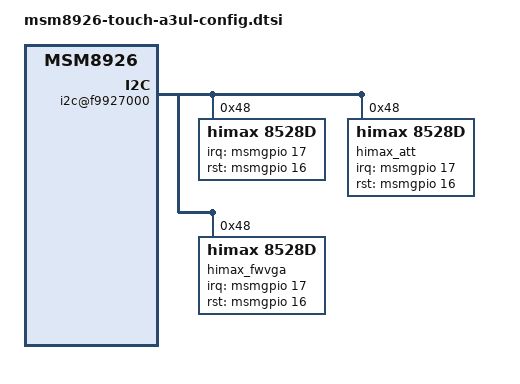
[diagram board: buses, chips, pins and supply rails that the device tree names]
/* Copyright (c) 2013, The Linux Foundation. All rights reserved.
 *
 * This program is free software; you can redistribute it and/or modify
 * it under the terms of the GNU General Public License version 2 and
 * only version 2 as published by the Free Software Foundation.
 *
 * This program is distributed in the hope that it will be useful,
 * but WITHOUT ANY WARRANTY; without even the implied warranty of
 * MERCHANTABILITY or FITNESS FOR A PARTICULAR PURPOSE.  See the
 * GNU General Public License for more details.
 */

&soc {
	i2c@f9927000 { /* BLSP1 QUP5 */
	himax@48 {
			compatible               	= "himax,8528d";
			reg                      		= <0x48>;
			interrupt-parent         	= <&msmgpio>;
			interrupts               	= <17 0x2>;
			himax,panel-coords   	= <0 810 0 1440>;
			himax,display-coords 	= <0 540 0 960>;
			himax,irq-gpio       	= <&msmgpio 17 0x00>;
			himax,rst-gpio       	= <&msmgpio 16 0x00>;
			report_type              	= <1>;

			config0 {	//YFO edge lamination
				sensor_id   	= <0x11>;
				himax,tw-coords   	= <0 810 0 1440>;
				himax,pl-coords 	= <0 540 0 960>;
				fw_ver     	= <0xC1>;
				c1 =[37 FF 08 FF 08];
				c2 =[3F 00];
				c3 =[62 01 00 21 00 00 00 00 00 11 11];
				c4 =[63 01 00 31 02 00 00 00 00 11 11];
				c5 =[64 01 00 21 03 00 00 00 00 11 11];
				c6 =[65 01 00 31 02 00 00 00 00 11 11];
				c7 =[66 01 00 21 03 00 00 00 00 11 11];
				c8 =[67 01 00 31 02 00 00 00 00 11 11];
				c9 =[68 01 00 21 03 00 00 00 00 11 11];
				c10 =[69 01 00 31 02 00 00 00 00 11 11];
				c11 =[6A 01 00 21 00 00 00 00 00 01 00];
				c12 =[6B 01 00 01 02 00 00 00 00 00 00];
				c13 =[6C 01 00 21 00 00 00 00 00 00 00];
				c14 =[6D 01 00 01 02 00 00 00 00 00 00];
				c15 =[6E 00 00 20 00 00 00 00 00 00 00];
				c16 =[6F 00 00 00 02 00 00 00 00 00 00];
				c17 =[70 00 00 00 00 00 00 00 00 00 00];
				c18 =[7B 03];
				c19 =[7C 00 D8 0C];
				c20 =[7F 00 04 0A 0A 04 00 00 00];
				c21 =[A4 94 62 94 86];
				c22 =[B4 05 01 02 02 02 04 07 05 07 05
				          07 05 07 08];
				c23 =[B9 01 36];
				c24 =[BA 00];
				c25 =[BB 00];
				c26 =[BC 00 00 00 00];
				c27 =[BD 04 0C];
				c28 =[C2 10 00 00 00 00 00 00 00];
				c29 =[C5 0C 1A 00 10 1A 1E 0B 1A 08 16];
				c30 =[C6 16 10 1E];
				c31 =[C9 00 00 00 10 12 14 16 18 1A 1C
				          20 22 24 26 11 13 15 17 19 1B
				          1D 21 23 25 00 00 00 00 00 00
				          00 00 00 00 00 00 00 00 00 00
				          00 00 00 00 00 00 00 00 00 00
				          00 00 00 00 00 00 00 00 00 00
				          00 00 00 00];
				c32 =[CB 01 F5 FF FF 01 00 05 00 7F 00
				          00 00];
				c33 =[D0 06 01];
				c34 =[D3 06 01];
				c35 =[D5 29 00 00 00 00 00 00 00 00 00
				          00 00 00 00 00 00];
				c36 =[40 0E 5A
				          5F 00 F0 10 00 00
				          38 0C 0B 12 0A 0C 0A 0C 0C 0C
				          24 20 40 40 3C 00 00 00 00 05
				          10 20];
				c37 =[40 94 08 80 83 84 00
				          48 24 0F 14 83 3C 00 00
				          11 00 41 42
				          0F 3F 00 12 00 00
				          10 02 3C 64 00 00];
				c38 =[40 18 47 47 04 14 00 00 00
				          04 06 24 05 05 00 00 00];
				c39 =[40 30 58 05 00 00 D8 0C 00 00 02
				          03 80 00 00 00 00
				          10 02 80 00 00 00 00 0C];
				c40 =[40 00 00 00 00 00 00 00 00
				          A0 82 2D 00
				          0C 15 A0 13
				          00 00 03 2A 05 A0];
				c41 =[40 04 A0 09 89 50 D5 08 00 7D 01
				          D4 49 CC 0C
				          06 AD 0D C5 56 2B 00 01 00 03
				          C0 4E 33 00];
				c42 =[40 00 00 00 00 00 00 00 00];
				c43_1 =[40 04 0C FF FF 08 0D 1A FF 03 0E
				             1B FF 09 0F 1C FF 02 10 1D FF
				             07 11 1E FF 05 12 1F FF 06 13
				             20];
				c43_2 =[40 FF 0A 14 FF FF 01 15 FF FF
				             0B 16 FF FF 00 17 FF FF FF 18
				             FF FF FF 19 FF FF FF FF FF FF];
				c44_1 =[40 A3 00 20 00 13 1E 32 00 00 00
				             00 00 00 00 00 00 00 00 00 00
				             00 00 00 00 00 00 00 00 00 00
				             56];
				c44_2 =[40 02 12 02 00 04];
				c45   =[40 00 00];
				};

			config1 {	//Henghao edge lamination
				sensor_id   	= <0x21>;
				himax,tw-coords   	= <0 810 0 1440>;
				himax,pl-coords 	= <0 540 0 960>;
				fw_ver     	= <0xC1>;
				c1 =[37 FF 08 FF 08];
				c2 =[3F 00];
				c3 =[62 01 00 21 00 00 00 00 00 33 33];
				c4 =[63 01 00 31 02 00 00 00 00 33 33];
				c5 =[64 01 00 21 03 00 00 00 00 33 33];
				c6 =[65 01 00 31 02 00 00 00 00 22 22];
				c7 =[66 01 00 21 03 00 00 00 00 22 22];
				c8 =[67 01 00 31 02 00 00 00 00 22 22];
				c9 =[68 01 00 21 03 00 00 00 00 22 22];
				c10 =[69 01 00 31 02 00 00 00 00 22 22];
				c11 =[6A 01 00 21 00 00 00 00 00 02 00];
				c12 =[6B 01 00 01 02 00 00 00 00 00 00];
				c13 =[6C 01 00 21 00 00 00 00 00 00 00];
				c14 =[6D 01 00 01 02 00 00 00 00 00 00];
				c15 =[6E 00 00 20 00 00 00 00 00 00 00];
				c16 =[6F 00 00 00 02 00 00 00 00 00 00];
				c17 =[70 00 00 00 00 00 00 00 00 00 00];
				c18 =[7B 03];
				c19 =[7C 00 D8 0C];
				c20 =[7F 00 04 0A 0A 04 00 00 00];
				c21 =[A4 94 62 94 86];
				c22 =[B4 06 01 02 02 02 03 0F 03 0F 03
				          0F 03 0F 08];
				c23 =[B9 01 36];
				c24 =[BA 00];
				c25 =[BB 00];
				c26 =[BC 00 00 00 00];
				c27 =[BD 04 0C];
				c28 =[C2 10 00 00 00 00 00 00 00];
				c29 =[C5 0A 1B 00 10 1A 1E 0B 1A 08 16];
				c30 =[C6 17 10 1E];
				c31 =[C9 00 00 00 26 24 22 20 1C 1A 18
				          16 14 12 10 25 23 21 1D 1B 19
				          17 15 13 11 00 00 00 00 00 00
				          00 00 00 00 00 00 00 00 00 00
				          00 00 00 00 00 00 00 00 00 00
				          00 00 00 00 00 00 00 00 00 00
				          00 00 00 00];
				c32 =[CB 01 F5 FF FF 01 00 05 00 5F 00
				          00 00];
				c33 =[D0 06 01];
				c34 =[D3 06 01];
				c35 =[D5 29 00 00 00 00 00 00 00 00 00
				          00 00 00 00 00 00];
				c36 =[40 0D 5A
				          5F 00 F0 10 00 00
				          38 0C 0B 12 0A 0C 0A 0C 0C 0C
				          24 20 40 40 3C 00 00 00 00 05
				          10 20];
				c37 =[40 94 08 80 83 84 00
				          48 24 0F 14 83 3C 00 00
				          11 00 41 42
				          0F 3F 00 12 00 00
				          10 02 3C 64 00 00];
				c38 =[40 18 3F 3F 04 14 00 00 00
				          04 06 24 06 06 00 00 00];
				c39 =[40 30 58 05 00 00 D8 0C 00 00 02
				          03 80 00 00 00 00
				          10 02 80 00 00 00 00 0C];
				c40 =[40 00 00 00 00 00 00 00 00
				          A0 82 2D 01
				          0C 15 A0 13
				          00 00 03 2A 05 A0];
				c41 =[40 04 A4 09 92 50 DD 08 00 7D 01
				          04 49 CC 0C
				          06 B1 0D CD 56 33 00 01 00 03
				          C0 4E 33 00];
				c42 =[40 00 00 00 00 00 00 00 00];
				c43_1 =[40 04 20 FF FF 08 1F 12 FF 03 1E
				             11 FF 09 1D 10 FF 02 1C 0F FF
				             07 1B 0E FF 05 1A 0D FF 06 19
				             0C];
				c43_2 =[40 FF 0A 18 FF FF 01 17 FF FF
				             0B 16 FF FF 00 15 FF FF FF 14
				             FF FF FF 13 FF FF FF FF FF FF];
				c44_1 =[40 A3 00 20 00 13 1E 32 00 00 00
				             00 00 00 00 00 00 00 00 00 00
				             00 00 00 00 00 00 00 00 00 00
				             56];
				c44_2 =[40 02 12 02 00 04];
				c45   =[40 00 00];
				};

			config2 {	//YFO edge lamination
				sensor_id   	= <0x22>;
				himax,tw-coords   	= <0 810 0 1440>;
				himax,pl-coords 	= <0 540 0 960>;
				fw_ver     	= <0xC1>;
				c1 =[37 FF 08 FF 08];
				c2 =[3F 00];
				c3 =[62 01 00 21 00 00 00 00 00 11 11];
				c4 =[63 01 00 31 02 00 00 00 00 11 11];
				c5 =[64 01 00 21 03 00 00 00 00 11 11];
				c6 =[65 01 00 31 02 00 00 00 00 11 11];
				c7 =[66 01 00 21 03 00 00 00 00 11 11];
				c8 =[67 01 00 31 02 00 00 00 00 11 11];
				c9 =[68 01 00 21 03 00 00 00 00 11 11];
				c10 =[69 01 00 31 02 00 00 00 00 11 11];
				c11 =[6A 01 00 21 00 00 00 00 00 01 00];
				c12 =[6B 01 00 01 02 00 00 00 00 00 00];
				c13 =[6C 01 00 21 00 00 00 00 00 00 00];
				c14 =[6D 01 00 01 02 00 00 00 00 00 00];
				c15 =[6E 00 00 20 00 00 00 00 00 00 00];
				c16 =[6F 00 00 00 02 00 00 00 00 00 00];
				c17 =[70 00 00 00 00 00 00 00 00 00 00];
				c18 =[7B 03];
				c19 =[7C 00 D8 0C];
				c20 =[7F 00 04 0A 0A 04 00 00 00];
				c21 =[A4 94 62 94 86];
				c22 =[B4 05 01 02 02 02 04 07 05 07 05
				          07 05 07 08];
				c23 =[B9 01 36];
				c24 =[BA 00];
				c25 =[BB 00];
				c26 =[BC 00 00 00 00];
				c27 =[BD 04 0C];
				c28 =[C2 10 00 00 00 00 00 00 00];
				c29 =[C5 0C 1A 00 10 1A 1E 0B 1A 08 16];
				c30 =[C6 16 10 1E];
				c31 =[C9 00 00 00 10 12 14 16 18 1A 1C
				          20 22 24 26 11 13 15 17 19 1B
				          1D 21 23 25 00 00 00 00 00 00
				          00 00 00 00 00 00 00 00 00 00
				          00 00 00 00 00 00 00 00 00 00
				          00 00 00 00 00 00 00 00 00 00
				          00 00 00 00];
				c32 =[CB 01 F5 FF FF 01 00 05 00 7F 00
				          00 00];
				c33 =[D0 06 01];
				c34 =[D3 06 01];
				c35 =[D5 29 00 00 00 00 00 00 00 00 00
				          00 00 00 00 00 00];
				c36 =[40 0E 5A
				          5F 00 F0 10 00 00
				          38 0C 0B 12 0A 0C 0A 0C 0C 0C
				          24 20 40 40 3C 00 00 00 00 05
				          10 20];
				c37 =[40 94 08 80 83 84 00
				          48 24 0F 14 83 3C 00 00
				          11 00 41 42
				          0F 3F 00 12 00 00
				          10 02 3C 64 00 00];
				c38 =[40 18 47 47 04 14 00 00 00
				          04 06 24 05 05 00 00 00];
				c39 =[40 30 58 05 00 00 D8 0C 00 00 02
				          03 80 00 00 00 00
				          10 02 80 00 00 00 00 0C];
				c40 =[40 00 00 00 00 00 00 00 00
				          A0 82 2D 00
				          0C 15 A0 13
				          00 00 03 2A 05 A0];
				c41 =[40 04 A0 09 89 50 D5 08 00 7D 01
				          D4 49 CC 0C
				          06 AD 0D C5 56 2B 00 01 00 03
				          C0 4E 33 00];
				c42 =[40 00 00 00 00 00 00 00 00];
				c43_1 =[40 04 0C FF FF 08 0D 1A FF 03 0E
				             1B FF 09 0F 1C FF 02 10 1D FF
				             07 11 1E FF 05 12 1F FF 06 13
				             20];
				c43_2 =[40 FF 0A 14 FF FF 01 15 FF FF
				             0B 16 FF FF 00 17 FF FF FF 18
				             FF FF FF 19 FF FF FF FF FF FF];
				c44_1 =[40 A3 00 20 00 13 1E 32 00 00 00
				             00 00 00 00 00 00 00 00 00 00
				             00 00 00 00 00 00 00 00 00 00
				             56];
				c44_2 =[40 02 12 02 00 04];
				c45   =[40 00 00];
				};

			config3 {	//ENR-semi 2
				sensor_id   	= <0x12>;
				himax,tw-coords   	= <0 810 0 1440>;
				himax,pl-coords 	= <0 540 0 960>;
				fw_ver     	= <0x04>;
				c1 = [ 37 FF 08 FF 08];
				c2 = [ 3F 00];
				c3 = [ 62 01 00 21 00 00 00 00 00 22 12];
				c4 = [ 63 01 00 31 02 00 00 00 00 12 12];
				c5 = [ 64 01 00 21 03 00 00 00 00 12 22];
				c6 = [ 65 01 00 31 02 00 00 00 00 22 22];
				c7 = [ 66 01 00 21 03 00 00 00 00 22 22];
				c8 = [ 67 01 00 31 02 00 00 00 00 22 22];
				c9 = [ 68 01 00 21 03 00 00 00 00 22 22];
				c10 =[ 69 01 00 31 02 00 00 00 00 22 22];
				c11 =[ 6A 01 00 21 00 00 00 00 00 02 00];
				c12 =[ 6B 01 00 01 02 00 00 00 00 00 00];
				c13 =[ 6C 01 00 21 00 00 00 00 00 00 00];
				c14 =[ 6D 01 00 01 02 00 00 00 00 00 00];
				c15 =[ 6E 00 00 20 00 00 00 00 00 00 00];
				c16 =[ 6F 00 00 00 02 00 00 00 00 00 00];
				c17 =[ 70 00 00 00 00 00 00 00 00 00 00];
				c18 =[ 7B 03];
				c19 =[ 7C 00 D8 8C];
				c20 =[ 7F 00 04 0A 0A 04 00 00 00];
				c21 =[ A4 94 62 94 86];
				c22 =[ B4 04 01 01 01 01 03 0F 04 07 04
				           07 04 07 00];
				c23 =[ B9 01 36];
				c24 =[ BA 00];
				c25 =[ BB 00];
				c26 =[ BC 00 00 00 00];
				c27 =[ BD 04 0C];
				c28 =[ C2 10 00 00 00 00 00 00 00];
				c29 =[ C5 0A 1C 00 10 19 1F 0B 1D 08 16];
				c30 =[ C6 16 10 1E];
				c31 =[ C9 00 00 00 26 24 22 20 1C 1A 18
				           16 14 12 10 25 23 21 1D 1B 19
				           17 15 13 11 00 00 00 00 00 00
				           00 00 00 00 00 00 00 00 00 00
				           00 00 00 00 00 00 00 00 00 00
				           00 00 00 00 00 00 00 00 00 00
				           00 00 00 00];
				c32 =[ CB 01 F5 FF FF 01 00 05 00 9F 00
				           00 00];
				c33 =[ D0 06 01];
				c34 =[ D3 06 01];
				c35 =[ D5 29 00 00 00 00 00 00 00 00 00
				           00 00 00 00 00 00];
				c36 =[ 40 01 5A
				           5F 00 00 10 00 00
				           28 0C 0A 10 06 06 0C 0F 0F 0F
				           20 20 30 5A 00 00 00 00 00 00
				           00 00];
				c37 =[ 40 64 08 80 82 85 00
				           35 25 0F 0F 83 3C 00 00
				           11 00 00 00
				           08 08 00 08 00 1A
				           10 02 10 64 00 00];
				c38 =[ 40 40 57 57 0A 14 00 00 00
				           04 03 12 06 06 00 00 00];
				c39 =[ 40 18 18 05 00 00 D8 8C 00 00 42
				           03 00 00 00 00 00
				           10 02 80 00 00 00 00 0C];
				c40 =[ 40 10 12 20 32 01 04 07 09
				           96 6E 32 00
				           0C 15 A0 13
				           00 00 03 2A 05 A0];
				c41 =[ 40 00 00 00 00 49 8C 00 00 00 00
				           00 47 F3 00
				           00 00 00 00 49 8C 00 00 00 00
				           00 47 F3 00];
				c42 =[ 40 00 00 00 00 00 00 00 00];
				c43_1 =[ 40 03 20 FF FF 04 1F 12 FF 05 1E
				              11 FF 06 1D 10 FF 07 1C 0F FF
				              02 1B 0E FF 01 1A 0D FF 00 19
				              0C];
				c43_2 =[ 40 FF 08 18 FF FF 09 17 FF FF
				              0A 16 FF FF 0B 15 FF FF FF 14
				              FF FF FF 13 FF FF FF FF FF FF];
				c44_1 =[ 40 A3 00 20 00 13 1E 32 00 00 00
				              00 00 00 00 00 00 00 00 00 00
				              00 00 00 00 00 00 00 00 00 00
				              00];
				c44_2 =[ 40 00 00 00 00 00];
				c45   =[ 40 19 00];
			};
		};

		himax_att@48 {
			compatible               	= "himax,8528d";
			reg                      		= <0x48>;
			interrupt-parent         	= <&msmgpio>;
			interrupts               	= <17 0x2>;
			himax,panel-coords   	= <0 810 0 1440>;
			himax,display-coords 	= <0 540 0 960>;
			himax,irq-gpio       	= <&msmgpio 17 0x00>;
			himax,rst-gpio       	= <&msmgpio 16 0x00>;
			report_type              	= <1>;

			config0 {	//CP3-semi 3
				sensor_id   	= <0x11>;
				himax,tw-coords   	= <0 810 0 1440>;
				himax,pl-coords 	= <0 540 0 960>;
				fw_ver     	= <0x04>;
				c1 =[37 FF 08 FF 08];
				c2 =[3F 00];
				c3 =[62 01 00 21 00 00 00 00 00 22 22];
				c4 =[63 01 00 31 02 00 00 00 00 22 22];
				c5 =[64 01 00 21 03 00 00 00 00 22 22];
				c6 =[65 01 00 31 02 00 00 00 00 22 22];
				c7 =[66 01 00 21 03 00 00 00 00 22 22];
				c8 =[67 01 00 31 02 00 00 00 00 22 22];
				c9 =[68 00 00 20 03 00 00 00 00 22 22];
				c10 =[69 00 00 00 02 00 00 00 00 22 22];
				c11 =[6A 01 00 21 00 00 00 00 00 22 22];
				c12 =[6B 01 00 01 02 00 00 00 00 00 00];
				c13 =[6C 01 00 21 00 00 00 00 00 00 00];
				c14 =[6D 01 00 01 02 00 00 00 00 00 00];
				c15 =[6E 00 00 20 00 00 00 00 00 00 00];
				c16 =[6F 00 00 00 02 00 00 00 00 00 00];
				c17 =[70 00 00 00 00 00 00 00 00 00 00];
				c18 =[7B 03];
				c19 =[7C 00 D8 0C];
				c20 =[7F 00 04 0A 0A 04 00 00 00];
				c21 =[A4 94 62 94 86];
				c22 =[B4 08 01 02 02 02 02 07 02 07 02
				              07 02 07 08];
				c23 =[B9 01 56];
				c24 =[BA 00];
				c25 =[BB 00];
				c26 =[BC 00 00 00 00];
				c27 =[BD 04 0C];
				c28 =[C2 10 00 00 00 00 00 00 00];
				c29 =[C5 0C 1F 00 10 1A 1E 0B 1A 08 16];
				c30 =[C6 15 10 1E];
				c31 =[C9 00 00 00 10 12 14 16 18 1A 1C
				          20 22 24 11 13 15 17 19 1B 1D
				          21 23 25 00 00 00 00 00 00 00
				          00 00 00 00 00 00 00 00 00 00
				          00 00 00 00 00 00 00 00 00 00
				          00 00 00 00 00 00 00 00 00 00
				          00 00 00 00];
				c32 =[CB 01 F5 FF FF 01 00 05 00 5F 00
				          00 00];
				c33 =[D0 06 01];
				c34 =[D3 06 01];
				c35 =[D5 29 00 00 00 00 00 00 00 00 00
				          00 00 00 00 00 00];
				c36 =[40 01 5A
				          5F 00 F0 10 00 00
				          38 0C 0B 10 0A 0A 0A 0F 0F 0F
				          28 1C 40 40 28 00 00 00 00 05
				          10 20];
				c37 =[40 75 08 80 83 84 00
				          50 28 0F 0F 83 3C 00 00
				          11 00 41 52
				          0F 18 00 12 00 00
				          10 02 3C 64 00 00];
				c38 =[40 28 27 27 02 14 00 00 00
				          04 06 24 08 08 00 00 00];
				c39 =[40 20 34 05 00 00 D8 0C 00 00 02
				          03 11 00 00 00 00
				          10 02 80 00 00 00 00 0C];
				c40 =[40 00 00 00 00 00 00 00 00
				          A0 82 1E 00
				          0A 14 A0 13
				          00 00 03 2A 05 A0];
				c41 =[40 00 00 00 00 59 E4 00 00 00 00
				          00 51 00 00
				          00 00 00 00 59 E4 00 00 00 00
				          00 51 00 00];
				c42 =[40 00 00 00 00 00 00 00 00];
				c43_1 =[40 04 0A FF FF 06 0B 18 FF 03 0C
				             19 FF 07 0D 1A FF 02 0E 1B FF
				             05 0F 1C FF FF 10 1D FF FF 11
				             FF];
				c43_2 =[40 FF 08 12 FF FF 01 13 FF FF
				             09 14 FF FF 00 15 FF FF FF 16
				             FF FF FF 17 FF FF FF FF FF FF];
				c44_1 =[40 A3 00 20 00 13 1E 32 00 00 00
				             00 00 00 00 00 00 00 00 00 00
				             00 00 00 00 00 00 00 00 00 00
				             56];
				c44_2 =[40 02 12 02 00 04];
				c45   =[40 00 00];
				};

			config1 {	//YFO full lamination
				sensor_id   	= <0x22>;
				himax,tw-coords   	= <0 810 0 1440>;
				himax,pl-coords 	= <0 540 0 960>;
				fw_ver     	= <0xC1>;
				c1 =[37 FF 08 FF 08];
				c2 =[3F 00];
				c3 =[62 01 00 21 00 00 00 00 00 11 11];
				c4 =[63 01 00 31 02 00 00 00 00 11 11];
				c5 =[64 01 00 21 03 00 00 00 00 11 11];
				c6 =[65 01 00 31 02 00 00 00 00 22 22];
				c7 =[66 01 00 21 03 00 00 00 00 22 22];
				c8 =[67 01 00 31 02 00 00 00 00 22 22];
				c9 =[68 01 00 21 03 00 00 00 00 22 22];
				c10 =[69 01 00 31 02 00 00 00 00 22 22];
				c11 =[6A 01 00 21 00 00 00 00 00 02 00];
				c12 =[6B 01 00 01 02 00 00 00 00 00 00];
				c13 =[6C 01 00 21 00 00 00 00 00 00 00];
				c14 =[6D 01 00 01 02 00 00 00 00 00 00];
				c15 =[6E 00 00 20 00 00 00 00 00 00 00];
				c16 =[6F 00 00 00 02 00 00 00 00 00 00];
				c17 =[70 00 00 00 00 00 00 00 00 00 00];
				c18 =[7B 03];
				c19 =[7C 00 D8 0C];
				c20 =[7F 00 04 0A 0A 04 00 00 00];
				c21 =[A4 94 62 94 86];
				c22 =[B4 05 01 02 02 02 04 07 05 07 05
				          07 05 07 08];
				c23 =[B9 01 36];
				c24 =[BA 00];
				c25 =[BB 00];
				c26 =[BC 00 00 00 00];
				c27 =[BD 04 0C];
				c28 =[C2 10 00 00 00 00 00 00 00];
				c29 =[C5 0C 1A 00 10 1A 1E 0B 1A 08 16];
				c30 =[C6 16 10 1E];
				c31 =[C9 00 00 00 10 12 14 16 18 1A 1C
				          20 22 24 26 11 13 15 17 19 1B
				          1D 21 23 25 00 00 00 00 00 00
				          00 00 00 00 00 00 00 00 00 00
				          00 00 00 00 00 00 00 00 00 00
				          00 00 00 00 00 00 00 00 00 00
				          00 00 00 00];
				c32 =[CB 01 F5 FF FF 01 00 05 00 7F 00
				          00 00];
				c33 =[D0 06 01];
				c34 =[D3 06 01];
				c35 =[D5 29 00 00 00 00 00 00 00 00 00
				          00 00 00 00 00 00];
				c36 =[40 04 5A
				          5F 00 F0 10 00 00
				          38 0C 0B 12 0A 0C 0A 0C 0C 0C
				          28 1C 40 40 1C 00 00 00 00 05
				          10 20];
				c37 =[40 94 08 80 83 84 00
				          50 28 0F 14 83 3C 00 00
				          11 00 41 42
				          0F 1F 00 12 00 00
				          10 02 3C 64 00 00];
				c38 =[40 18 47 47 04 14 00 00 00
				          04 06 24 05 05 00 00 00];
				c39 =[40 30 60 05 00 00 D8 0C 00 00 02
				          03 00 00 00 00 00
				          10 02 80 00 00 00 00 0C];
				c40 =[40 00 00 00 00 00 00 00 00
				          A0 82 1E 00
				          0C 15 A0 13
				          00 00 03 2A 05 A0];
				c41 =[40 04 A0 09 89 50 D5 08 00 7D 01
				          D4 49 CC 0C
				          06 AD 0D C5 56 2B 00 01 00 03
				          C0 4E 33 00];
				c42 =[40 00 00 00 00 00 00 00 00];
				c43_1 =[40 04 0C FF FF 08 0D 1A FF 03 0E
				             1B FF 09 0F 1C FF 02 10 1D FF
				             07 11 1E FF 05 12 1F FF 06 13
				             20];
				c43_2 =[40 FF 0A 14 FF FF 01 15 FF FF
				             0B 16 FF FF 00 17 FF FF FF 18
				             FF FF FF 19 FF FF FF FF FF FF];
				c44_1 =[40 A3 00 20 00 13 1E 32 00 00 00
				             00 00 00 00 00 00 00 00 00 00
				             00 00 00 00 00 00 00 00 00 00
				             56];
				c44_2 =[40 02 12 02 00 04];
				c45   =[40 00 00];
				};

			config2 {	//ENR-semi 2
				sensor_id   	= <0x12>;
				himax,tw-coords   	= <0 810 0 1440>;
				himax,pl-coords 	= <0 540 0 960>;
				fw_ver     	= <0x04>;
				c1 = [ 37 FF 08 FF 08];
				c2 = [ 3F 00];
				c3 = [ 62 01 00 21 00 00 00 00 00 22 12];
				c4 = [ 63 01 00 31 02 00 00 00 00 12 12];
				c5 = [ 64 01 00 21 03 00 00 00 00 12 22];
				c6 = [ 65 01 00 31 02 00 00 00 00 22 22];
				c7 = [ 66 01 00 21 03 00 00 00 00 22 22];
				c8 = [ 67 01 00 31 02 00 00 00 00 22 22];
				c9 = [ 68 01 00 21 03 00 00 00 00 22 22];
				c10 =[ 69 01 00 31 02 00 00 00 00 22 22];
				c11 =[ 6A 01 00 21 00 00 00 00 00 02 00];
				c12 =[ 6B 01 00 01 02 00 00 00 00 00 00];
				c13 =[ 6C 01 00 21 00 00 00 00 00 00 00];
				c14 =[ 6D 01 00 01 02 00 00 00 00 00 00];
				c15 =[ 6E 00 00 20 00 00 00 00 00 00 00];
				c16 =[ 6F 00 00 00 02 00 00 00 00 00 00];
				c17 =[ 70 00 00 00 00 00 00 00 00 00 00];
				c18 =[ 7B 03];
				c19 =[ 7C 00 D8 8C];
				c20 =[ 7F 00 04 0A 0A 04 00 00 00];
				c21 =[ A4 94 62 94 86];
				c22 =[ B4 04 01 01 01 01 03 0F 04 07 04
				           07 04 07 00];
				c23 =[ B9 01 36];
				c24 =[ BA 00];
				c25 =[ BB 00];
				c26 =[ BC 00 00 00 00];
				c27 =[ BD 04 0C];
				c28 =[ C2 10 00 00 00 00 00 00 00];
				c29 =[ C5 0A 1C 00 10 19 1F 0B 1D 08 16];
				c30 =[ C6 16 10 1E];
				c31 =[ C9 00 00 00 26 24 22 20 1C 1A 18
				           16 14 12 10 25 23 21 1D 1B 19
				           17 15 13 11 00 00 00 00 00 00
				           00 00 00 00 00 00 00 00 00 00
				           00 00 00 00 00 00 00 00 00 00
				           00 00 00 00 00 00 00 00 00 00
				           00 00 00 00];
				c32 =[ CB 01 F5 FF FF 01 00 05 00 9F 00
				           00 00];
				c33 =[ D0 06 01];
				c34 =[ D3 06 01];
				c35 =[ D5 29 00 00 00 00 00 00 00 00 00
				           00 00 00 00 00 00];
				c36 =[ 40 01 5A
				           5F 00 00 10 00 00
				           28 0C 0A 10 06 06 0C 0F 0F 0F
				           20 20 30 5A 00 00 00 00 00 00
				           00 00];
				c37 =[ 40 64 08 80 82 85 00
				           35 25 0F 0F 83 3C 00 00
				           11 00 00 00
				           08 08 00 08 00 1A
				           10 02 10 64 00 00];
				c38 =[ 40 40 57 57 0A 14 00 00 00
				           04 03 12 06 06 00 00 00];
				c39 =[ 40 18 18 05 00 00 D8 8C 00 00 42
				           03 00 00 00 00 00
				           10 02 80 00 00 00 00 0C];
				c40 =[ 40 10 12 20 32 01 04 07 09
				           96 6E 32 00
				           0C 15 A0 13
				           00 00 03 2A 05 A0];
				c41 =[ 40 00 00 00 00 49 8C 00 00 00 00
				           00 47 F3 00
				           00 00 00 00 49 8C 00 00 00 00
				           00 47 F3 00];
				c42 =[ 40 00 00 00 00 00 00 00 00];
				c43_1 =[ 40 03 20 FF FF 04 1F 12 FF 05 1E
				              11 FF 06 1D 10 FF 07 1C 0F FF
				              02 1B 0E FF 01 1A 0D FF 00 19
				              0C];
				c43_2 =[ 40 FF 08 18 FF FF 09 17 FF FF
				              0A 16 FF FF 0B 15 FF FF FF 14
				              FF FF FF 13 FF FF FF FF FF FF];
				c44_1 =[ 40 A3 00 20 00 13 1E 32 00 00 00
				              00 00 00 00 00 00 00 00 00 00
				              00 00 00 00 00 00 00 00 00 00
				              00];
				c44_2 =[ 40 00 00 00 00 00];
				c45   =[ 40 19 00];
				};
		};

		himax_fwvga@48 {
			compatible               	= "himax,8528d";
			reg                      		= <0x48>;
			interrupt-parent         	= <&msmgpio>;
			interrupts               	= <17 0x2>;
			himax,panel-coords   	= <0 720 0 1280>;
			himax,display-coords 	= <0 480 0 854>;
			himax,irq-gpio       	= <&msmgpio 17 0x00>;
			himax,rst-gpio       	= <&msmgpio 16 0x00>;
			report_type              	= <1>;

			config0 {	//YFO edge lamination
				sensor_id   	= <0x11>;
				himax,tw-coords   	= <0 720 0 1280>;
				himax,pl-coords 	= <0 480 0 854>;
				fw_ver     	= <0xC1>;
				c1 =[37 FF 08 FF 08];
				c2 =[3F 00];
				c3 =[62 01 00 21 00 00 00 00 00 11 11];
				c4 =[63 01 00 31 02 00 00 00 00 11 11];
				c5 =[64 01 00 21 03 00 00 00 00 11 11];
				c6 =[65 01 00 31 02 00 00 00 00 11 11];
				c7 =[66 01 00 21 03 00 00 00 00 11 11];
				c8 =[67 01 00 31 02 00 00 00 00 11 11];
				c9 =[68 01 00 21 03 00 00 00 00 11 11];
				c10 =[69 01 00 31 02 00 00 00 00 11 11];
				c11 =[6A 01 00 21 00 00 00 00 00 01 00];
				c12 =[6B 01 00 01 02 00 00 00 00 00 00];
				c13 =[6C 01 00 21 00 00 00 00 00 00 00];
				c14 =[6D 01 00 01 02 00 00 00 00 00 00];
				c15 =[6E 00 00 20 00 00 00 00 00 00 00];
				c16 =[6F 00 00 00 02 00 00 00 00 00 00];
				c17 =[70 00 00 00 00 00 00 00 00 00 00];
				c18 =[7B 03];
				c19 =[7C 00 D8 0C];
				c20 =[7F 00 04 0A 0A 04 00 00 00];
				c21 =[A4 94 62 94 86];
				c22 =[B4 05 01 02 02 02 04 07 05 07 05
				          07 05 07 08];
				c23 =[B9 01 36];
				c24 =[BA 00];
				c25 =[BB 00];
				c26 =[BC 00 00 00 00];
				c27 =[BD 04 0C];
				c28 =[C2 10 00 00 00 00 00 00 00];
				c29 =[C5 0C 1A 00 10 1A 1E 0B 1A 08 16];
				c30 =[C6 16 10 1E];
				c31 =[C9 00 00 00 10 12 14 16 18 1A 1C
				          20 22 24 26 11 13 15 17 19 1B
				          1D 21 23 25 00 00 00 00 00 00
				          00 00 00 00 00 00 00 00 00 00
				          00 00 00 00 00 00 00 00 00 00
				          00 00 00 00 00 00 00 00 00 00
				          00 00 00 00];
				c32 =[CB 01 F5 FF FF 01 00 05 00 7F 00
				          00 00];
				c33 =[D0 06 01];
				c34 =[D3 06 01];
				c35 =[D5 29 00 00 00 00 00 00 00 00 00
				          00 00 00 00 00 00];
				c36 =[40 0E 5A
				          5F 00 F0 10 00 00
				          38 0C 0B 12 0A 0C 0A 0C 0C 0C
				          24 20 40 40 3C 00 00 00 00 05
				          10 20];
				c37 =[40 94 08 80 83 84 00
				          48 24 0F 14 83 3C 00 00
				          11 00 41 42
				          0F 3F 00 12 00 00
				          10 02 3C 64 00 00];
				c38 =[40 18 47 47 04 14 00 00 00
				          04 06 24 05 05 00 00 00];
				c39 =[40 30 58 05 00 00 D8 0C 00 00 02
				          03 80 00 00 00 00
				          10 02 80 00 00 00 00 0C];
				c40 =[40 00 00 00 00 00 00 00 00
				          A0 82 2D 00
				          0C 15 A0 13
				          00 00 02 D0 05 01];
				c41 =[40 03 E2 08 01 47 3F 08 00 61 01
				          6A 41 28 0C
				          05 EF 0C 3D 4C 95 00 00 E4 03
				          56 45 8F 00];
				c42 =[40 00 00 00 00 00 00 00 00];
				c43_1 =[40 04 0C FF FF 08 0D 1A FF 03 0E
				             1B FF 09 0F 1C FF 02 10 1D FF
				             07 11 1E FF 05 12 1F FF 06 13
				             20];
				c43_2 =[40 FF 0A 14 FF FF 01 15 FF FF
				             0B 16 FF FF 00 17 FF FF FF 18
				             FF FF FF 19 FF FF FF FF FF FF];
				c44_1 =[40 A3 00 20 00 13 1E 32 00 00 00
				             00 00 00 00 00 00 00 00 00 00
				             00 00 00 00 00 00 00 00 00 00
				             56];
				c44_2 =[40 02 12 02 00 04];
				c45   =[40 00 00];
				};

			config1 {	//YFO edge lamination
				sensor_id   	= <0x22>;
				himax,tw-coords   	= <0 720 0 1280>;
				himax,pl-coords 	= <0 480 0 854>;
				fw_ver     	= <0xC1>;
				c1 =[37 FF 08 FF 08];
				c2 =[3F 00];
				c3 =[62 01 00 21 00 00 00 00 00 11 11];
				c4 =[63 01 00 31 02 00 00 00 00 11 11];
				c5 =[64 01 00 21 03 00 00 00 00 11 11];
				c6 =[65 01 00 31 02 00 00 00 00 11 11];
				c7 =[66 01 00 21 03 00 00 00 00 11 11];
				c8 =[67 01 00 31 02 00 00 00 00 11 11];
				c9 =[68 01 00 21 03 00 00 00 00 11 11];
				c10 =[69 01 00 31 02 00 00 00 00 11 11];
				c11 =[6A 01 00 21 00 00 00 00 00 01 00];
				c12 =[6B 01 00 01 02 00 00 00 00 00 00];
				c13 =[6C 01 00 21 00 00 00 00 00 00 00];
				c14 =[6D 01 00 01 02 00 00 00 00 00 00];
				c15 =[6E 00 00 20 00 00 00 00 00 00 00];
				c16 =[6F 00 00 00 02 00 00 00 00 00 00];
				c17 =[70 00 00 00 00 00 00 00 00 00 00];
				c18 =[7B 03];
				c19 =[7C 00 D8 0C];
				c20 =[7F 00 04 0A 0A 04 00 00 00];
				c21 =[A4 94 62 94 86];
				c22 =[B4 05 01 02 02 02 04 07 05 07 05
				          07 05 07 08];
				c23 =[B9 01 36];
				c24 =[BA 00];
				c25 =[BB 00];
				c26 =[BC 00 00 00 00];
				c27 =[BD 04 0C];
				c28 =[C2 10 00 00 00 00 00 00 00];
				c29 =[C5 0C 1A 00 10 1A 1E 0B 1A 08 16];
				c30 =[C6 16 10 1E];
				c31 =[C9 00 00 00 10 12 14 16 18 1A 1C
				          20 22 24 26 11 13 15 17 19 1B
				          1D 21 23 25 00 00 00 00 00 00
				          00 00 00 00 00 00 00 00 00 00
				          00 00 00 00 00 00 00 00 00 00
				          00 00 00 00 00 00 00 00 00 00
				          00 00 00 00];
				c32 =[CB 01 F5 FF FF 01 00 05 00 7F 00
				          00 00];
				c33 =[D0 06 01];
				c34 =[D3 06 01];
				c35 =[D5 29 00 00 00 00 00 00 00 00 00
				          00 00 00 00 00 00];
				c36 =[40 0E 5A
				          5F 00 F0 10 00 00
				          38 0C 0B 12 0A 0C 0A 0C 0C 0C
				          24 20 40 40 3C 00 00 00 00 05
				          10 20];
				c37 =[40 94 08 80 83 84 00
				          48 24 0F 14 83 3C 00 00
				          11 00 41 42
				          0F 3F 00 12 00 00
				          10 02 3C 64 00 00];
				c38 =[40 18 47 47 04 14 00 00 00
				          04 06 24 05 05 00 00 00];
				c39 =[40 30 58 05 00 00 D8 0C 00 00 02
				          03 80 00 00 00 00
				          10 02 80 00 00 00 00 0C];
				c40 =[40 00 00 00 00 00 00 00 00
				          A0 82 2D 00
				          0C 15 A0 13
				          00 00 02 D0 05 01];
				c41 =[40 03 E2 08 01 47 3F 08 00 61 01
				          6A 41 28 0C
				          05 EF 0C 3D 4C 95 00 00 E4 03
				          56 45 8F 00];
				c42 =[40 00 00 00 00 00 00 00 00];
				c43_1 =[40 04 0C FF FF 08 0D 1A FF 03 0E
				             1B FF 09 0F 1C FF 02 10 1D FF
				             07 11 1E FF 05 12 1F FF 06 13
				             20];
				c43_2 =[40 FF 0A 14 FF FF 01 15 FF FF
				             0B 16 FF FF 00 17 FF FF FF 18
				             FF FF FF 19 FF FF FF FF FF FF];
				c44_1 =[40 A3 00 20 00 13 1E 32 00 00 00
				             00 00 00 00 00 00 00 00 00 00
				             00 00 00 00 00 00 00 00 00 00
				             56];
				c44_2 =[40 02 12 02 00 04];
				c45   =[40 00 00];
			};

			config2 {	//ENR-semi 2
				sensor_id   	= <0x12>;
				himax,tw-coords   	= <0 720 0 1280>;
				himax,pl-coords 	= <0 480 0 854>;
				fw_ver     	= <0x04>;
				c1 = [37 FF 08 FF 08];
				c2 = [3F 00];
				c3 = [62 01 00 21 00 00 00 00 00 22 12];
				c4 = [63 01 00 31 02 00 00 00 00 12 12];
				c5 = [64 01 00 21 03 00 00 00 00 12 22];
				c6 = [65 01 00 31 02 00 00 00 00 22 22];
				c7 = [66 01 00 21 03 00 00 00 00 22 22];
				c8 = [67 01 00 31 02 00 00 00 00 22 22];
				c9 = [68 01 00 21 03 00 00 00 00 22 22];
				c10 =[69 01 00 31 02 00 00 00 00 22 22];
				c11 =[6A 01 00 21 00 00 00 00 00 02 00];
				c12 =[6B 01 00 01 02 00 00 00 00 00 00];
				c13 =[6C 01 00 21 00 00 00 00 00 00 00];
				c14 =[6D 01 00 01 02 00 00 00 00 00 00];
				c15 =[6E 00 00 20 00 00 00 00 00 00 00];
				c16 =[6F 00 00 00 02 00 00 00 00 00 00];
				c17 =[70 00 00 00 00 00 00 00 00 00 00];
				c18 =[7B 03];
				c19 =[7C 00 D8 8C];
				c20 =[7F 00 04 0A 0A 04 00 00 00];
				c21 =[A4 94 62 94 86];
				c22 =[B4 04 01 01 01 01 03 0F 04 07 04
				          07 04 07 00];
				c23 =[B9 01 36];
				c24 =[BA 00];
				c25 =[BB 00];
				c26 =[BC 00 00 00 00];
				c27 =[BD 04 0C];
				c28 =[C2 10 00 00 00 00 00 00 00];
				c29 =[C5 0A 1C 00 10 19 1F 0B 1D 08 16];
				c30 =[C6 16 10 1E];
				c31 =[C9 00 00 00 26 24 22 20 1C 1A 18
				          16 14 12 10 25 23 21 1D 1B 19
				          17 15 13 11 00 00 00 00 00 00
				          00 00 00 00 00 00 00 00 00 00
				          00 00 00 00 00 00 00 00 00 00
				          00 00 00 00 00 00 00 00 00 00
				          00 00 00 00];
				c32 =[CB 01 F5 FF FF 01 00 05 00 9F 00
				          00 00];
				c33 =[D0 06 01];
				c34 =[D3 06 01];
				c35 =[D5 29 00 00 00 00 00 00 00 00 00
				          00 00 00 00 00 00];
				c36 =[40 01 5A
				          5F 00 00 10 00 00
				          28 0C 0A 10 06 06 0C 0F 0F 0F
				          20 20 30 5A 00 00 00 00 00 00
				          00 00];
				c37 =[40 64 08 80 82 85 00
				          35 25 0F 0F 83 3C 00 00
				          11 00 00 00
				          08 08 00 08 00 1A
				          10 02 10 64 00 00];
				c38 =[40 40 57 57 0A 14 00 00 00
				          04 03 12 06 06 00 00 00];
				c39 =[40 18 18 05 00 00 D8 8C 00 00 42
				          03 00 00 00 00 00
				          10 02 80 00 00 00 00 0C];
				c40 =[40 10 12 20 32 01 04 07 09
				          96 6E 32 00
				          0C 15 A0 13
				          00 00 02 D0 05 01];
				c41 =[40 00 00 00 00 41 5D 00 00 00 00
				          00 40 00 00
				          00 00 00 00 41 5D 00 00 00 00
				          00 40 00 00];
				c42 =[40 00 00 00 00 00 00 00 00];
				c43_1 =[40 03 20 FF FF 04 1F 12 FF 05 1E
				             11 FF 06 1D 10 FF 07 1C 0F FF
				             02 1B 0E FF 01 1A 0D FF 00 19
				             0C];
				c43_2 =[40 FF 08 18 FF FF 09 17 FF FF
				             0A 16 FF FF 0B 15 FF FF FF 14
				             FF FF FF 13 FF FF FF FF FF FF];
				c44_1 =[40 A3 00 20 00 13 1E 32 00 00 00
				             00 00 00 00 00 00 00 00 00 00
				             00 00 00 00 00 00 00 00 00 00
				             00];
				c44_2 =[40 00 00 00 00 00];
				c45   =[40 19 00];
			};
		};
	};
};

